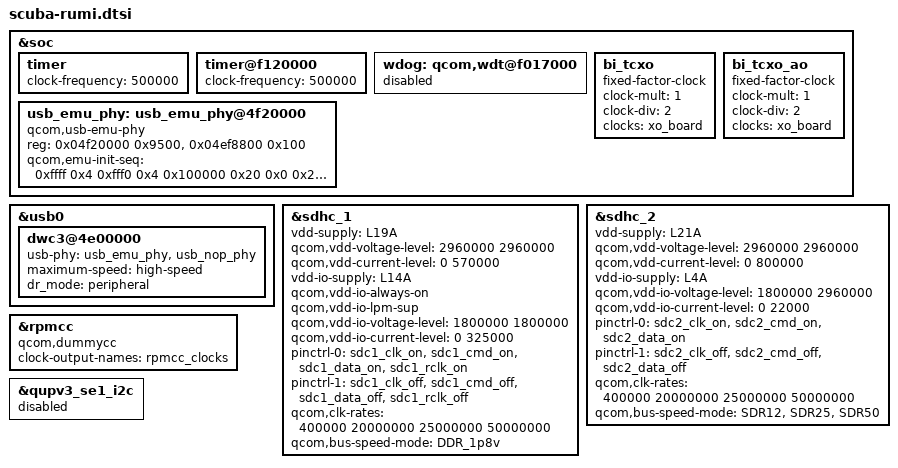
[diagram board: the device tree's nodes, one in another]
&soc {
	timer {
		clock-frequency = <500000>;
	};

	timer@f120000 {
		clock-frequency = <500000>;
	};

	wdog: qcom,wdt@f017000 {
		status = "disabled";
	};

	usb_emu_phy: usb_emu_phy@4f20000 {
			compatible = "qcom,usb-emu-phy";
			reg = <0x04f20000 0x9500>,
				<0x04ef8800 0x100>;
			reg-names = "base", "qscratch_base";

			qcom,emu-init-seq = <0xffff 0x4
					     0xfff0 0x4
					     0x100000 0x20
					     0x0 0x20
					     0x101f0 0x20
					     0x100000 0x3c
					     0x0 0x3c
					     0x10060 0x3c
					     0x0 0x4>;
	};

	bi_tcxo: bi_tcxo {
		compatible = "fixed-factor-clock";
		clock-mult = <1>;
		clock-div = <2>;
		clocks = <&xo_board>;
		#clock-cells = <0>;
	};

	bi_tcxo_ao: bi_tcxo_ao {
		compatible = "fixed-factor-clock";
		clock-mult = <1>;
		clock-div = <2>;
		clocks = <&xo_board>;
		#clock-cells = <0>;
	};
};

&usb0 {
	dwc3@4e00000 {
		usb-phy = <&usb_emu_phy>, <&usb_nop_phy>;
		maximum-speed = "high-speed";
		dr_mode = "peripheral";
	};
};

&sdhc_1 {
	vdd-supply = <&L19A>;
	qcom,vdd-voltage-level = <2960000 2960000>;
	qcom,vdd-current-level = <0 570000>;

	vdd-io-supply = <&L14A>;
	qcom,vdd-io-always-on;
	qcom,vdd-io-lpm-sup;
	qcom,vdd-io-voltage-level = <1800000 1800000>;
	qcom,vdd-io-current-level = <0 325000>;

	pinctrl-names = "active", "sleep";
	pinctrl-0 = <&sdc1_clk_on &sdc1_cmd_on &sdc1_data_on
					&sdc1_rclk_on>;
	pinctrl-1 = <&sdc1_clk_off &sdc1_cmd_off &sdc1_data_off
					&sdc1_rclk_off>;

	qcom,clk-rates = <400000 20000000 25000000 50000000>;
	qcom,bus-speed-mode = "DDR_1p8v";

	/delete-property/qcom,devfreq,freq-table;

	status = "ok";
};

&sdhc_2 {
	vdd-supply = <&L21A>;
	qcom,vdd-voltage-level = <2960000 2960000>;
	qcom,vdd-current-level = <0 800000>;

	vdd-io-supply = <&L4A>;
	qcom,vdd-io-voltage-level = <1800000 2960000>;
	qcom,vdd-io-current-level = <0 22000>;

	pinctrl-names = "active", "sleep";
	pinctrl-0 = <&sdc2_clk_on  &sdc2_cmd_on &sdc2_data_on>;
	pinctrl-1 = <&sdc2_clk_off &sdc2_cmd_off &sdc2_data_off>;

	qcom,clk-rates = <400000 20000000 25000000 50000000>;
	qcom,bus-speed-mode = "SDR12", "SDR25", "SDR50";

	/delete-property/qcom,devfreq,freq-table;

	status = "ok";
};

&rpmcc {
	compatible = "qcom,dummycc";
	clock-output-names = "rpmcc_clocks";
	#clock-cells = <1>;
	#reset-cells = <1>;
};

&qupv3_se1_i2c {
	status = "disabled";
};
